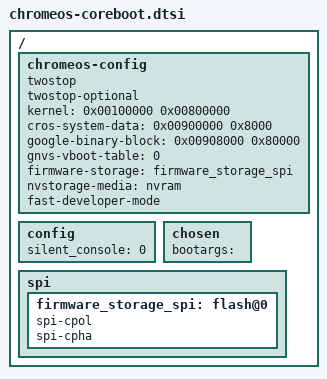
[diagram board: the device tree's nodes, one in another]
/*
 * Copyright (c) 2011 The Chromium OS Authors. All rights reserved.
 * Use of this source code is governed by a BSD-style license that can be
 * found in the LICENSE file.
 */

/*
 * This file holds Chrome OS-specific options, kept within a chromeos-config
 */

/ {
	chromeos-config {
		twostop;		/* Two-stop boot */
		twostop-optional;       /* One-stop optimization enabled */

		/* Memory addresses for kernel, cros-system and gbb */
		kernel = <0x00100000 0x00800000>;
		cros-system-data = <0x00900000 0x8000>;
		google-binary-block = <0x00908000 0x80000>;

		/* This value will be filled in by coreboot at runtime */
		gnvs-vboot-table = <0>;

		firmware-storage = <&firmware_storage_spi>;
		nvstorage-media = "nvram";

		/* Only wait 2s in developer mode screen */
		fast-developer-mode;
	};

	config {
		silent_console = <0>;
	};

	chosen {
		bootargs = "";
	};

	/* Use default values */
	spi {
		firmware_storage_spi: flash@0 {
		      spi-cpol;
		      spi-cpha;
		};
	};
};
